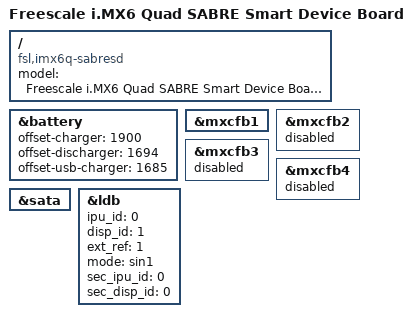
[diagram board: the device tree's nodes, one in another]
/*
 * Copyright 2012 Freescale Semiconductor, Inc.
 * Copyright 2011 Linaro Ltd.
 *
 * The code contained herein is licensed under the GNU General Public
 * License. You may obtain a copy of the GNU General Public License
 * Version 2 or later at the following locations:
 *
 * http://www.opensource.org/licenses/gpl-license.html
 * http://www.gnu.org/copyleft/gpl.html
 */

/dts-v1/;

#include "imx6q.dtsi"
#include "imx6qdl-sabresd.dtsi"

/ {
	model = "Freescale i.MX6 Quad SABRE Smart Device Board";
	compatible = "fsl,imx6q-sabresd", "fsl,imx6q";
};

&battery {
	offset-charger = <1900>;
	offset-discharger = <1694>;
	offset-usb-charger = <1685>;
};

&mxcfb1 {
	status = "okay";
};


&mxcfb2 {
	status = "disabled";
};

&mxcfb3 {
	status = "disabled";
};

&mxcfb4 {
	status = "disabled";
};

&sata {
	status = "okay";
};

&ldb {
	ipu_id = <0>;
	disp_id = <1>;
	ext_ref = <1>;
	mode = "sin1";
	sec_ipu_id = <0>;
	sec_disp_id = <0>;
	status = "okay";
};
